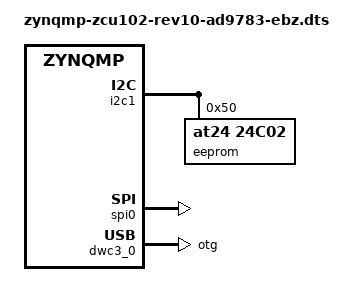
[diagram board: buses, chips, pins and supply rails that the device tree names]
// SPDX-License-Identifier: GPL-2.0
/*
 * Analog Devices AD-FMCOMMS2-EBZ/AD-FMCOMMS3-EBZ
 * https://wiki.analog.com/resources/eval/user-guides/ad-fmcomms2-ebz
 * https://wiki.analog.com/resources/eval/user-guides/ad-fmcomms3-ebz
 *
 * hdl_project: <fmcomms2/zcu102>
 * board_revision: <>
 *
 * Copyright (C) 2014-2019 Analog Devices Inc.
 */

#include "zynqmp-zcu102-rev1.0.dts"
#include <dt-bindings/interrupt-controller/irq.h>

&i2c1 {
	i2c-mux@75 {
		i2c@0 {
			#address-cells = <1>;
			#size-cells = <0>;
			reg = <0>;
			/* HPC0_IIC */
			eeprom@50 {
				compatible = "at24,24c02";
				reg = <0x50>;
			};

		};
	};
};

/ {
	fpga_axi: fpga-axi@0 {
		interrupt-parent = <&gic>;
		compatible = "simple-bus";
		#address-cells = <0x1>;
		#size-cells = <0x1>;
		ranges = <0 0 0 0xffffffff>;


		axi_sysid_0: axi-sysid-0@85000000 {
			compatible = "adi,axi-sysid-1.00.a";
			reg = <0x85000000 0x10000>;
		};
	};
};

&spi0 {
	status = "okay";
};

&dwc3_0 {
	status = "okay";
	dr_mode = "otg";
};

#define fmc_spi spi0
